VERSION ""

NS_ :

BS_:

BU_:

BO_ 2415919102 TIRE_Signals: 40 Vector__XXX
 SG_ SenseError33 : 307|1@1+ (1,0) [0|1] "" Vector__XXX
 SG_ SenseError32 : 306|1@1+ (1,0) [0|1] "" Vector__XXX
 SG_ SenseError31 : 305|1@1+ (1,0) [0|1] "" Vector__XXX
 SG_ SenseError30 : 304|1@1+ (1,0) [0|1] "" Vector__XXX
 SG_ SenseError23 : 303|1@1+ (1,0) [0|1] "" Vector__XXX
 SG_ SenseError22 : 302|1@1+ (1,0) [0|1] "" Vector__XXX
 SG_ SenseError21 : 301|1@1+ (1,0) [0|1] "" Vector__XXX
 SG_ SenseError20 : 300|1@1+ (1,0) [0|1] "" Vector__XXX
 SG_ SenseError13 : 299|1@1+ (1,0) [0|1] "" Vector__XXX
 SG_ SenseError12 : 298|1@1+ (1,0) [0|1] "" Vector__XXX
 SG_ SenseError11 : 297|1@1+ (1,0) [0|1] "" Vector__XXX
 SG_ SenseError10 : 296|1@1+ (1,0) [0|1] "" Vector__XXX
 SG_ SenseError01 : 295|1@1+ (1,0) [0|1] "" Vector__XXX
 SG_ SenseError00 : 294|1@1+ (1,0) [0|1] "" Vector__XXX
 SG_ TemperatureWarning33 : 293|1@1+ (1,0) [0|1] "" Vector__XXX
 SG_ TemperatureWarning32 : 292|1@1+ (1,0) [0|1] "" Vector__XXX
 SG_ TemperatureWarning31 : 291|1@1+ (1,0) [0|1] "" Vector__XXX
 SG_ TemperatureWarning30 : 290|1@1+ (1,0) [0|1] "" Vector__XXX
 SG_ TemperatureWarning23 : 289|1@1+ (1,0) [0|1] "" Vector__XXX
 SG_ TemperatureWarning22 : 288|1@1+ (1,0) [0|1] "" Vector__XXX
 SG_ TemperatureWarning21 : 287|1@1+ (1,0) [0|1] "" Vector__XXX
 SG_ TemperatureWarning20 : 286|1@1+ (1,0) [0|1] "" Vector__XXX
 SG_ TemperatureWarning13 : 285|1@1+ (1,0) [0|1] "" Vector__XXX
 SG_ TemperatureWarning12 : 284|1@1+ (1,0) [0|1] "" Vector__XXX
 SG_ TemperatureWarning11 : 283|1@1+ (1,0) [0|1] "" Vector__XXX
 SG_ TemperatureWarning10 : 282|1@1+ (1,0) [0|1] "" Vector__XXX
 SG_ TemperatureWarning01 : 281|1@1+ (1,0) [0|1] "" Vector__XXX
 SG_ TemperatureWarning00 : 280|1@1+ (1,0) [0|1] "" Vector__XXX
 SG_ LeakageWarning33 : 279|1@1+ (1,0) [0|1] "" Vector__XXX
 SG_ LeakageWarning32 : 278|1@1+ (1,0) [0|1] "" Vector__XXX
 SG_ LeakageWarning31 : 277|1@1+ (1,0) [0|1] "" Vector__XXX
 SG_ LeakageWarning30 : 276|1@1+ (1,0) [0|1] "" Vector__XXX
 SG_ LeakageWarning23 : 275|1@1+ (1,0) [0|1] "" Vector__XXX
 SG_ LeakageWarning22 : 274|1@1+ (1,0) [0|1] "" Vector__XXX
 SG_ LeakageWarning21 : 273|1@1+ (1,0) [0|1] "" Vector__XXX
 SG_ LeakageWarning20 : 272|1@1+ (1,0) [0|1] "" Vector__XXX
 SG_ LeakageWarning13 : 271|1@1+ (1,0) [0|1] "" Vector__XXX
 SG_ LeakageWarning12 : 270|1@1+ (1,0) [0|1] "" Vector__XXX
 SG_ LeakageWarning11 : 269|1@1+ (1,0) [0|1] "" Vector__XXX
 SG_ LeakageWarning10 : 268|1@1+ (1,0) [0|1] "" Vector__XXX
 SG_ LeakageWarning01 : 267|1@1+ (1,0) [0|1] "" Vector__XXX
 SG_ LeakageWarning00 : 266|1@1+ (1,0) [0|1] "" Vector__XXX
 SG_ PressureWarning33 : 265|1@1+ (1,0) [0|1] "" Vector__XXX
 SG_ PressureWarning32 : 264|1@1+ (1,0) [0|1] "" Vector__XXX
 SG_ PressureWarning31 : 263|1@1+ (1,0) [0|1] "" Vector__XXX
 SG_ PressureWarning30 : 262|1@1+ (1,0) [0|1] "" Vector__XXX
 SG_ PressureWarning23 : 261|1@1+ (1,0) [0|1] "" Vector__XXX
 SG_ PressureWarning22 : 260|1@1+ (1,0) [0|1] "" Vector__XXX
 SG_ PressureWarning21 : 259|1@1+ (1,0) [0|1] "" Vector__XXX
 SG_ PressureWarning20 : 258|1@1+ (1,0) [0|1] "" Vector__XXX
 SG_ PressureWarning13 : 257|1@1+ (1,0) [0|1] "" Vector__XXX
 SG_ PressureWarning12 : 256|1@1+ (1,0) [0|1] "" Vector__XXX
 SG_ PressureWarning11 : 255|1@1+ (1,0) [0|1] "" Vector__XXX
 SG_ PressureWarning10 : 254|1@1+ (1,0) [0|1] "" Vector__XXX
 SG_ PressureWarning01 : 253|1@1+ (1,0) [0|1] "" Vector__XXX
 SG_ PressureWarning00 : 252|1@1+ (1,0) [0|1] "" Vector__XXX
 SG_ TireTemp33 : 244|8@1+ (1,-40) [-40|215] "" Vector__XXX
 SG_ TireTemp32 : 236|8@1+ (1,-40) [-40|215] "" Vector__XXX
 SG_ TireTemp31 : 228|8@1+ (1,-40) [-40|215] "" Vector__XXX
 SG_ TireTemp30 : 220|8@1+ (1,-40) [-40|215] "" Vector__XXX
 SG_ TireTemp23 : 212|8@1+ (1,-40) [-40|215] "" Vector__XXX
 SG_ TireTemp22 : 204|8@1+ (1,-40) [-40|215] "" Vector__XXX
 SG_ TireTemp21 : 196|8@1+ (1,-40) [-40|215] "" Vector__XXX
 SG_ TireTemp20 : 188|8@1+ (1,-40) [-40|215] "" Vector__XXX
 SG_ TireTemp13 : 180|8@1+ (1,-40) [-40|215] "" Vector__XXX
 SG_ TireTemp12 : 172|8@1+ (1,-40) [-40|215] "" Vector__XXX
 SG_ TireTemp11 : 164|8@1+ (1,-40) [-40|215] "" Vector__XXX
 SG_ TireTemp10 : 156|8@1+ (1,-40) [-40|215] "" Vector__XXX
 SG_ TireTemp01 : 148|8@1+ (1,-40) [-40|215] "" Vector__XXX
 SG_ TireTemp00 : 140|8@1+ (1,-40) [-40|215] "" Vector__XXX
 SG_ TirePress33 : 130|10@1+ (1,0) [0|1023] "" Vector__XXX
 SG_ TirePress32 : 120|10@1+ (1,0) [0|1023] "" Vector__XXX
 SG_ TirePress31 : 110|10@1+ (1,0) [0|1023] "" Vector__XXX
 SG_ TirePress30 : 100|10@1+ (1,0) [0|1023] "" Vector__XXX
 SG_ TirePress23 : 90|10@1+ (1,0) [0|1023] "" Vector__XXX
 SG_ TirePress22 : 80|10@1+ (1,0) [0|1023] "" Vector__XXX
 SG_ TirePress21 : 70|10@1+ (1,0) [0|1023] "" Vector__XXX
 SG_ TirePress20 : 60|10@1+ (1,0) [0|1023] "" Vector__XXX
 SG_ TirePress13 : 50|10@1+ (1,0) [0|1023] "" Vector__XXX
 SG_ TirePress12 : 40|10@1+ (1,0) [0|1023] "" Vector__XXX
 SG_ TirePress11 : 30|10@1+ (1,0) [0|1023] "" Vector__XXX
 SG_ TirePress10 : 20|10@1+ (1,0) [0|1023] "" Vector__XXX
 SG_ TirePress01 : 10|10@1+ (1,0) [0|1023] "" Vector__XXX
 SG_ TirePress00 : 0|10@1+ (1,0) [0|1023] "" Vector__XXX

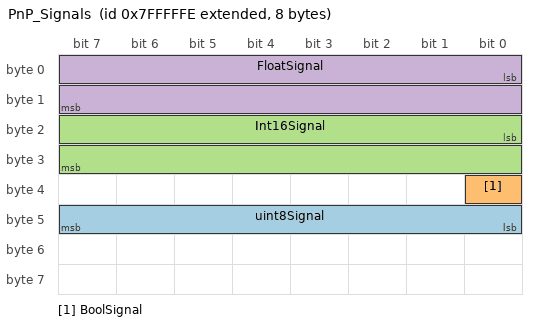
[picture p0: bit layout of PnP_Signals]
BO_ 2281701374 PnP_Signals: 8 Vector__XXX
 SG_ uint8Signal : 40|8@1+ (1,0) [0|255] "" Vector__XXX
 SG_ BoolSignal : 32|1@1+ (1,0) [0|0] "" Vector__XXX
 SG_ Int16Signal : 16|16@1+ (1,-32768) [0|0] "" Vector__XXX
 SG_ FloatSignal : 0|16@1+ (0.1,-3276.8) [0|0] "" Vector__XXX

CM_ "$File: //depot/auto/dbc/EtalonMessages/TPMS/0.1.0.0/TPMS_etalon.dbc $
$Change: 215848 $
$DateTime: 2024/08/14 16:25:49 $
$Revision: #1 $";
BA_DEF_ SG_  "SigType" ENUM  "Default","Range","RangeSigned","ASCII","Discrete","Control","ReferencePGN","DTC","StringDelimiter","StringLength","StringLengthControl","MessageCounter","MessageChecksum";
BA_DEF_ SG_  "GenSigEVName" STRING ;
BA_DEF_ SG_  "GenSigILSupport" ENUM  "No","Yes";
BA_DEF_ SG_  "GenSigSendType" ENUM  "Cyclic","OnWrite","OnWriteWithRepetition","OnChange","OnChangeWithRepetition","IfActive","IfActiveWithRepetition","NoSigSendType";
BA_DEF_ SG_  "GenSigStartValue" INT 0 2147483647;
BA_DEF_ BO_  "GenMsgILSupport" ENUM  "No","Yes";
BA_DEF_ BU_  "NmStationAddress" INT 0 255;
BA_DEF_ BO_  "GenMsgSendType" ENUM  "cyclic","NotUsed","IfActive","NotUsed","NotUsed","NotUsed","NotUsed","NotUsed","noMsgSendType";
BA_DEF_ BO_  "GenMsgRequestable" INT 0 1;
BA_DEF_  "DBName" STRING ;
BA_DEF_  "BusType" STRING ;
BA_DEF_  "ProtocolType" STRING ;
BA_DEF_ BO_  "VFrameFormat" ENUM  "StandardCAN","ExtendedCAN","reserved","J1939PG";
BA_DEF_DEF_  "SigType" "Default";
BA_DEF_DEF_  "GenSigEVName" "Env@Nodename_@Signame";
BA_DEF_DEF_  "GenSigILSupport" "Yes";
BA_DEF_DEF_  "GenSigSendType" "NoSigSendType";
BA_DEF_DEF_  "GenSigStartValue" 0;
BA_DEF_DEF_  "GenMsgILSupport" "Yes";
BA_DEF_DEF_  "NmStationAddress" 254;
BA_DEF_DEF_  "GenMsgSendType" "noMsgSendType";
BA_DEF_DEF_  "GenMsgRequestable" 1;
BA_DEF_DEF_  "DBName" "";
BA_DEF_DEF_  "BusType" "CAN";
BA_DEF_DEF_  "ProtocolType" "J1939";
BA_DEF_DEF_  "VFrameFormat" "J1939PG";
BA_ "DBName" "TPMS_etalon";
BA_ "GenSigStartValue" SG_ 2415919102 TireTemp33 40;
BA_ "GenSigStartValue" SG_ 2415919102 TireTemp32 40;
BA_ "GenSigStartValue" SG_ 2415919102 TireTemp31 40;
BA_ "GenSigStartValue" SG_ 2415919102 TireTemp30 40;
BA_ "GenSigStartValue" SG_ 2415919102 TireTemp23 40;
BA_ "GenSigStartValue" SG_ 2415919102 TireTemp22 40;
BA_ "GenSigStartValue" SG_ 2415919102 TireTemp21 40;
BA_ "GenSigStartValue" SG_ 2415919102 TireTemp20 40;
BA_ "GenSigStartValue" SG_ 2415919102 TireTemp13 40;
BA_ "GenSigStartValue" SG_ 2415919102 TireTemp12 40;
BA_ "GenSigStartValue" SG_ 2415919102 TireTemp11 40;
BA_ "GenSigStartValue" SG_ 2415919102 TireTemp10 40;
BA_ "GenSigStartValue" SG_ 2415919102 TireTemp01 40;
BA_ "GenSigStartValue" SG_ 2415919102 TireTemp00 40;
